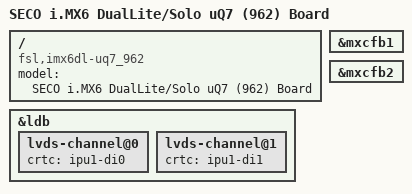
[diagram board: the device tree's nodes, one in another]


/dts-v1/;

#include "imx6dl.dtsi"
#include "imx6qdl-seco_uq7_962.dtsi"
#include "imx6qdl-seco_lvds_display.dtsi"

/ {
	model = "SECO i.MX6 DualLite/Solo uQ7 (962) Board";
	compatible = "fsl,imx6dl-uq7_962", "fsl,imx6dl";
};


&ldb {
	lvds-channel@0 {
		crtc = "ipu1-di0";
	};

	lvds-channel@1 {
		crtc = "ipu1-di1";
	};
};

&mxcfb1 {
	status = "okay";
};

&mxcfb2 {
	status = "okay";
};
